AUTOSAR XML (schema 00048)
package /ara/demo/applications
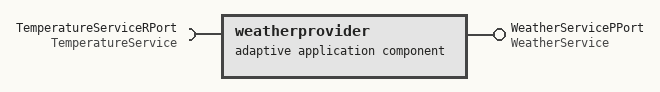
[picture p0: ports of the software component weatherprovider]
  adaptive application sw component type weatherprovider
    provide port WeatherServicePPort: provided-interface=WeatherService
    require port TemperatureServiceRPort: required-interface=TemperatureService
package /ara/demo/executables
  executable weatherprovider_exe: category=APPLICATION_LEVEL, build-type=BUILD-TYPE-DEBUG, logging-behavior=USES-LOGGING, minimum-timer-granularity=1000.0
    root sw component prototype root_swc: application-type=weatherprovider
